# STM32F410 register map
File version: 1.3
CPU: CM4 r0p1, little endian, MPU, FPU, 4 interrupt priority bits
Registers are 32-bit, read-write, reset 0x0 unless marked. A register's access mark holds for its fields unless they carry their own. Offsets are from the block's base; [hi:lo] are bit positions; {n}, {i} and the like mark numbered series.

## EXTI — External interrupt/event controller
Base 0x40013C00
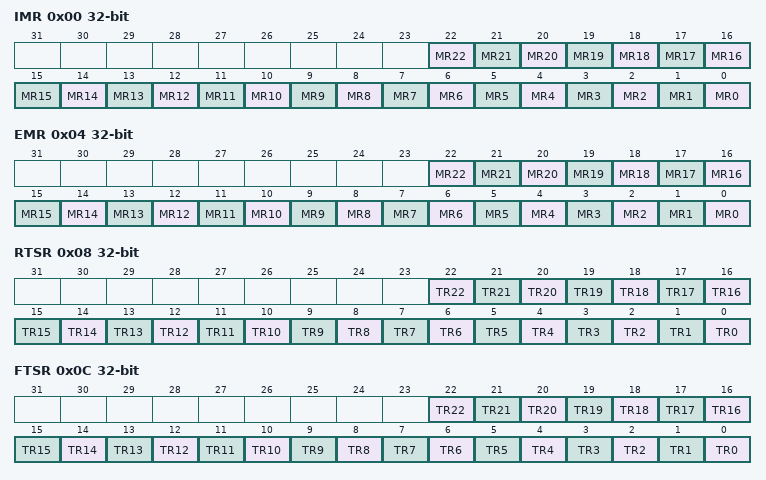
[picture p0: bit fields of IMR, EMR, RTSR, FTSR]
0x00 IMR — Interrupt mask register (EXTI_IMR)
  [n] MR{n} (n=0..22) — Interrupt Mask on line {n}
0x04 EMR — Event mask register (EXTI_EMR)
  [n] MR{n} (n=0..22) — Event Mask on line {n}
0x08 RTSR — Rising Trigger selection register (EXTI_RTSR)
  [n] TR{n} (n=0..22) — Rising trigger event configuration of line {n}
0x0C FTSR — Falling Trigger selection register (EXTI_FTSR)
  [n] TR{n} (n=0..22) — Falling trigger event configuration of line {n}
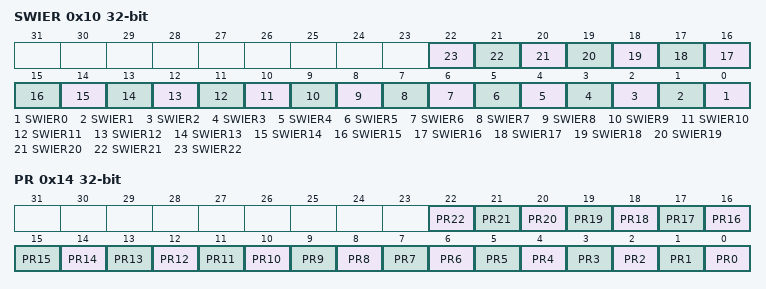
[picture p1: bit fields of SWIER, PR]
0x10 SWIER — Software interrupt event register (EXTI_SWIER)
  [n] SWIER{n} (n=0..22) — Software Interrupt on line {n}
0x14 PR — Pending register (EXTI_PR)
  [n] PR{n} (n=0..22) — Pending bit {n}

## FLASH
Base 0x40023C00
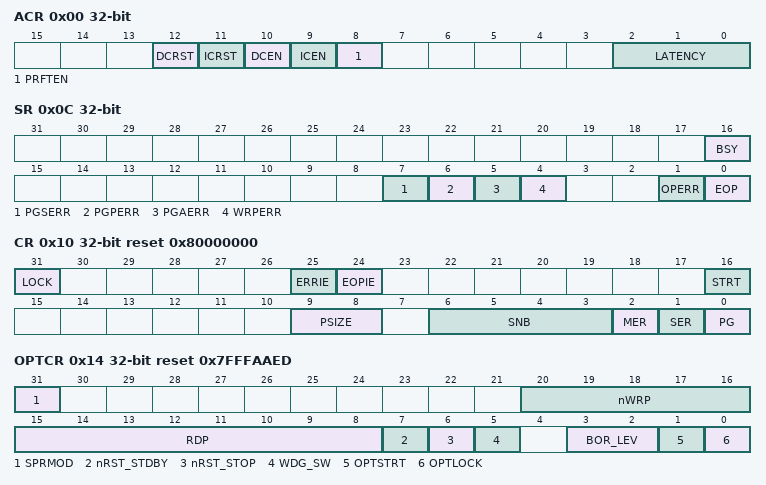
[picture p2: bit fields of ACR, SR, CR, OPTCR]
0x00 ACR access per field — Flash access control register
  [12] DCRST rw — Data cache reset
  [11] ICRST wo — Instruction cache reset
  [10] DCEN rw — Data cache enable
  [9] ICEN rw — Instruction cache enable
  [8] PRFTEN rw — Prefetch enable
  [2:0] LATENCY rw
0x04 KEYR wo — Flash key register
  [31:0] KEY — FPEC key
0x08 OPTKEYR wo — Flash option key register
  [31:0] OPTKEY — Option byte key
0x0C SR access per field — Status register
  [16] BSY ro — Busy
  [7] PGSERR rw — Programming sequence error
  [6] PGPERR rw — Programming parallelism error
  [5] PGAERR rw — Programming alignment error
  [4] WRPERR rw — Write protection error
  [1] OPERR rw — Operation error
  [0] EOP rw — End of operation
0x10 CR reset 0x80000000 — Control register
  [31] LOCK
  [25] ERRIE — Error interrupt enable
  [24] EOPIE — End of operation interrupt enable
  [16] STRT — Start
  [9:8] PSIZE — Program size
  [6:3] SNB — Sector number
  [2] MER — Mass Erase
  [1] SER — Sector Erase
  [0] PG — Programming
0x14 OPTCR reset 0x7FFFAAED — Flash option control register
  [31] SPRMOD
  [20:16] nWRP — Not write protect
  [15:8] RDP — Read protect
  [7] nRST_STDBY — nRST_STDBY User option bytes
  [6] nRST_STOP — nRST_STOP User option bytes
  [5] WDG_SW — WDG_SW User option bytes
  [3:2] BOR_LEV — BOR reset Level
  [1] OPTSTRT — Option start
  [0] OPTLOCK — Option lock

## IWDG — Independent watchdog
Base 0x40003000
0x00 KR wo — Key register
  [15:0] KEY — Key value
0x04 PR — Prescaler register
  [2:0] PR — Prescaler divider
0x08 RLR reset 0xFFF — Reload register
  [11:0] RL — Watchdog counter reload value
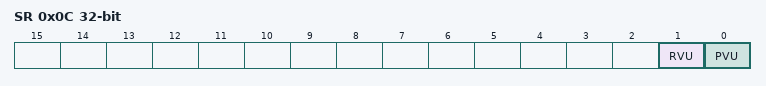
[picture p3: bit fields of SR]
0x0C SR ro — Status register
  [1] RVU — Watchdog counter reload value update
  [0] PVU — Watchdog prescaler value update

## PWR — Power control
Base 0x40007000
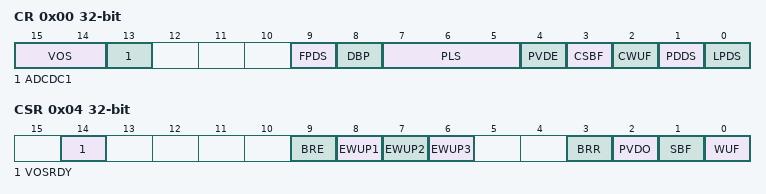
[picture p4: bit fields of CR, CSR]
0x00 CR — power control register
  [15:14] VOS — Regulator voltage scaling output selection
  [13] ADCDC1
  [9] FPDS — Flash power down in Stop mode
  [8] DBP — Disable backup domain write protection
  [7:5] PLS — PVD level selection
  [4] PVDE — Power voltage detector enable
  [3] CSBF — Clear standby flag
  [2] CWUF — Clear wakeup flag
  [1] PDDS — Power down deepsleep
  [0] LPDS — Low-power deep sleep
0x04 CSR access per field — power control/status register
  [14] VOSRDY rw — Regulator voltage scaling output selection ready bit
  [9] BRE rw — Backup regulator enable
  [8] EWUP1 rw — Enable WKUP1 pin
  [7] EWUP2 rw — Enable WKUP2 pin
  [6] EWUP3 rw — Enable WKUP3 pin
  [3] BRR ro — Backup regulator ready
  [2] PVDO ro — PVD output
  [1] SBF ro — Standby flag
  [0] WUF ro — Wakeup flag

## SYSCFG — System configuration controller
Base 0x40013800
0x00 MEMRM — memory remap register
  [1:0] MEM_MODE
0x04 PMC — peripheral mode configuration register
  [16] ADC1DC2
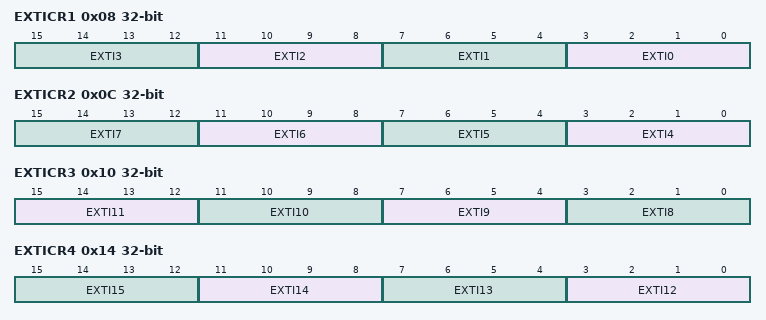
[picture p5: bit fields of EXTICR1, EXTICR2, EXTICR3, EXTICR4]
0x08 EXTICR1 — external interrupt configuration register 1
  [4n+3:4n] EXTI{n} (n=0..3) — EXTI x configuration (x = 0 to 3)
0x0C EXTICR2 — external interrupt configuration register 2
  [4n-13:4n-16] EXTI{n} (n=4..7) — EXTI x configuration (x = 4 to 7)
0x10 EXTICR3 — external interrupt configuration register 3
  [15:12] EXTI11 — EXTI x configuration (x = 8 to 11)
  [11:8] EXTI10
  [7:4] EXTI9 — EXTI x configuration (x = 8 to 11)
  [3:0] EXTI8 — EXTI x configuration (x = 8 to 11)
0x14 EXTICR4 — external interrupt configuration register 4
  [4n-45:4n-48] EXTI{n} (n=12..15) — EXTI x configuration (x = 12 to 15)
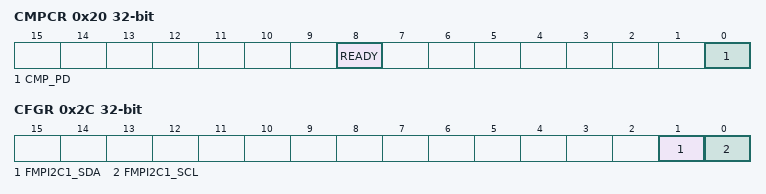
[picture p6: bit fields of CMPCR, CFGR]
0x20 CMPCR ro — Compensation cell control register
  [8] READY
  [0] CMP_PD — Compensation cell power-down
0x2C CFGR — Configuration register
  [1] FMPI2C1_SDA, [0] FMPI2C1_SCL
